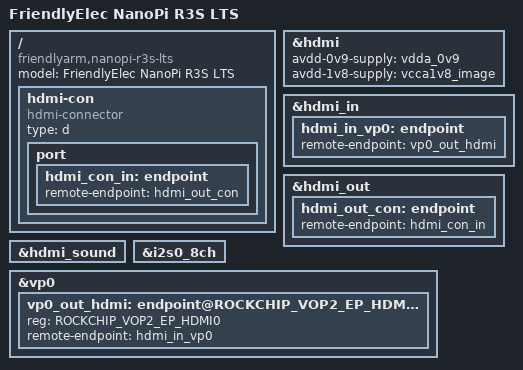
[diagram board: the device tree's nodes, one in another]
// SPDX-License-Identifier: GPL-2.0-or-later OR MIT
/*
 * Copyright (c) 2020 Rockchip Electronics Co., Ltd.
 * Copyright (c) 2024 FriendlyElec Computer Tech. Co., Ltd.
 * (http://www.friendlyelec.com)
 */

/dts-v1/;

#include "rk3566-nanopi-r3s.dts"

/ {
	compatible = "friendlyarm,nanopi-r3s-lts", "rockchip,rk3566";
	model = "FriendlyElec NanoPi R3S LTS";

	hdmi-con {
		compatible = "hdmi-connector";
		type = "d";

		port {
			hdmi_con_in: endpoint {
				remote-endpoint = <&hdmi_out_con>;
			};
		};
	};
};

&hdmi {
	avdd-0v9-supply = <&vdda_0v9>;
	avdd-1v8-supply = <&vcca1v8_image>;
	status = "okay";
};

&hdmi_in {
	hdmi_in_vp0: endpoint {
		remote-endpoint = <&vp0_out_hdmi>;
	};
};

&hdmi_out {
	hdmi_out_con: endpoint {
		remote-endpoint = <&hdmi_con_in>;
	};
};

&hdmi_sound {
	status = "okay";
};

&i2s0_8ch {
	status = "okay";
};

&vp0 {
	vp0_out_hdmi: endpoint@ROCKCHIP_VOP2_EP_HDMI0 {
		reg = <ROCKCHIP_VOP2_EP_HDMI0>;
		remote-endpoint = <&hdmi_in_vp0>;
	};
};
